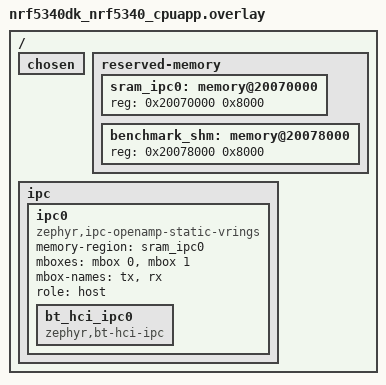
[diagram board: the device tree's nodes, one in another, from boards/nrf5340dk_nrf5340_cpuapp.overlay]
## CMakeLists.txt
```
# SPDX-License-Identifier: Apache-2.0

cmake_minimum_required(VERSION 3.20.0)

# YOUR BOARD HERE
# set(ENV{BOARD} nrf52840dk/nrf52840)
# set(ENV{BOARD} nrf5340dk/nrf5340/cpuapp)
#set(ENV{BOARD} nrf5340dk/nrf5340/cpunet)
# set(ENV{BOARD} nrf54l15dk/nrf54l15/cpuapp)

#find_package(Zephyr)
find_package(Zephyr REQUIRED HINTS $ENV{ZEPHYR_BASE})
project(ble-framework)

FILE(GLOB app_sources src/*.c)
target_sources(app PRIVATE ${app_sources})

zephyr_include_directories(
        ${CMAKE_CURRENT_SOURCE_DIR}/include
)

zephyr_include_directories_ifdef(
        CONFIG_SOC_COMPATIBLE_NRF53X
        ${CMAKE_CURRENT_SOURCE_DIR}/common_nRF5340/include
)
```

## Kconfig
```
config BENCHMARK_AUTO_DUT
	bool "Run the benchmark batch autonomously after boot (Device B / DUT on PPK II)"
	help
	  The DUT initializes, advertises, accepts the pairing of Device A and,
	  once Device A has subscribed, sends all payload sizes from
	  auto_benchmark.c on its own. The results are sent to Device A over the
	  results characteristic, so the DUT's serial terminal is never needed.
	  Build with -DEXTRA_CONF_FILE=auto_dut.conf.

config BENCHMARK_IDLE_TEST
	bool "Idle current test: step through sleep / timer / BLE phases (Device B on PPK II)"
	depends on !BENCHMARK_AUTO_DUT && SOC_COMPATIBLE_NRF52X
	help
	  Measures what the benchmark timer and Bluetooth add to the idle current.
	  See src/idle_test.c, evaluate with data_processing/idle_test.py.
	  Build with -DEXTRA_CONF_FILE=idle_test.conf.

source "Kconfig.zephyr"
```

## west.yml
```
# app_attacks/west.yml:
manifest:
  remotes:
    - name: zephyr_attacks
      url-base: https://github.com/HannahGress
  projects:
    - name: zephyr_attacks
      remote: zephyr_attacks
      revision: benchmarking-time
      import: true
```

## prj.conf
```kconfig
#
# Copyright (c) 2018 Nordic Semiconductor
#
# SPDX-License-Identifier: LicenseRef-Nordic-5-Clause
#
# Enable Security Management Protocol
CONFIG_BT_SMP=y

# Logger module
#CONFIG_LOG=y
#CONFIG_BT_LOG_SNIFFER_INFO=y
#CONFIG_LOG_PROCESS_THREAD=y
# allows to make sent packages visible ("Wireshark")
#CONFIG_BT_SMP_LOG_LEVEL_DBG=y
#CONFIG_LOG_MODE_OVERFLOW=y

#CONFIG_LOG_BUFFER_SIZE=4096

#CONFIG_BT_HCI_ERR_TO_STR=y
#CONFIG_BT_HCI_CORE_LOG_LEVEL_INF=y

CONFIG_BT=y
CONFIG_BT_CENTRAL=y
CONFIG_BT_PERIPHERAL=y
CONFIG_BT_BROADCASTER=y
CONFIG_BT_GATT_CLIENT=y
CONFIG_BT_DEVICE_NAME="BLE Framework"
# CONFIG_BT_PRIVACY gives the DK/Central a RPA instead a NRPA
CONFIG_BT_PRIVACY=y
CONFIG_BT_MAX_CONN=5
CONFIG_BT_BONDABLE=y
CONFIG_BT_SMP_APP_PAIRING_ACCEPT=y
# When a bond is about to complete, find any other bond with the same
# peer address (or IRK) and `bt_unpair` that bond before the event `pairing_complete`.
#BT_ID_UNPAIR_MATCHING_BONDS=y

# setting configurations to allow flash handling
CONFIG_BT_SETTINGS=y
CONFIG_FLASH=y
CONFIG_FLASH_PAGE_LAYOUT=y
CONFIG_FLASH_MAP=y
CONFIG_NVS=y
CONFIG_SETTINGS=y
CONFIG_SETTINGS_RUNTIME=y

# Increase the number of maximum paired devices
CONFIG_BT_MAX_PAIRED=5
CONFIG_BT_ID_MAX=20

# Increase stack size for the main thread and System Workqueue
CONFIG_SYSTEM_WORKQUEUE_STACK_SIZE=2048
CONFIG_MAIN_STACK_SIZE=2048
CONFIG_BT_RX_STACK_SIZE=2048
# CONFIG_BT_HCI_TX_STACK_SIZE_WITH_PROMPT=y
CONFIG_BT_HCI_TX_STACK_SIZE=1024

CONFIG_SHELL=y

CONFIG_BT_SMP_SC_ONLY=n
CONFIG_BT_SMP_SC_PAIR_ONLY=n

# enable data length extension
# CONFIG_BT_CTLR_DATA_LENGTH=y
CONFIG_BT_CTLR_DATA_LENGTH_MAX=251
CONFIG_BT_BUF_ACL_TX_SIZE=251
CONFIG_BT_BUF_ACL_RX_SIZE=251
CONFIG_BT_L2CAP_TX_MTU=247

CONFIG_BT_SMP_MIN_ENC_KEY_SIZE=7

# stop the scan to repeatedly showing the same devices/AD packets
CONFIG_BT_CTLR_DUP_FILTER_LEN=128

# CONFIG_SOC_NRF53_CPUNET_ENABLE=y

# to enable %f when printing (shell or printf), so printing of double and float
CONFIG_CBPRINTF_FP_SUPPORT=y

# if one board lost/deleted the LTK, pairing is started from scratch instead of throwing a pairing failure
CONFIG_BT_SMP_ALLOW_UNAUTH_OVERWRITE=y

# connection interval 100 ms (units of 1.25 ms), gives Device A more time per received packet
# The Peripheral requests these values ~5 s after connecting, and cmd_connect() uses the same
# values as Central, so the interval does not change during a measurement.
# Timeout 4 s (units of 10 ms), must be > 2 * interval
CONFIG_BT_PERIPHERAL_PREF_MIN_INT=80
CONFIG_BT_PERIPHERAL_PREF_MAX_INT=80
CONFIG_BT_PERIPHERAL_PREF_LATENCY=0
CONFIG_BT_PERIPHERAL_PREF_TIMEOUT=400
```

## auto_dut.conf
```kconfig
# Device B (DUT): run the benchmark batch autonomously after boot
# build with -DEXTRA_CONF_FILE=auto_dut.conf
CONFIG_BENCHMARK_AUTO_DUT=y

# ###########################################################################
# /!\ THE SERIAL SHELL OF THIS BUILD IS DISABLED /!\
#
# The UART keeps drawing ~1 mA even without USB, which distorts the current
# measurement. Shell output goes to a dummy backend (nowhere) instead, so the
# serial terminal of Device B shows NOTHING and accepts NO commands.
#
# To talk to Device B over its serial terminal again, delete or comment out
# the three lines below and rebuild + reflash (or use the normal build).
# ###########################################################################
# SHELL_BACKEND_SERIAL selects SERIAL, so without this line SERIAL silently stays y
CONFIG_SHELL_BACKEND_SERIAL=n
CONFIG_SERIAL=n
CONFIG_SHELL_BACKEND_DUMMY=y
```

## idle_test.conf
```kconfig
# Device B: idle current test, see src/idle_test.c and data_processing/idle_test.py
# build with -DEXTRA_CONF_FILE=idle_test.conf
CONFIG_BENCHMARK_IDLE_TEST=y

# serial shell disabled like in auto_dut.conf: the UART alone draws ~1 mA
# SHELL_BACKEND_SERIAL selects SERIAL, so it has to be switched off too, otherwise SERIAL stays y
CONFIG_SHELL_BACKEND_SERIAL=n
CONFIG_SERIAL=n
CONFIG_SHELL_BACKEND_DUMMY=y
```

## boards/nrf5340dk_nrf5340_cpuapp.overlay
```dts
/delete-node/ &sram0_shared;

/ {
	chosen {
		/delete-property/ zephyr,ipc_shm;
	};

	reserved-memory {
		#address-cells = <1>;
		#size-cells = <1>;
		ranges;

		sram_ipc0: memory@20070000 {
			reg = <0x20070000 0x8000>;
		};

		benchmark_shm: memory@20078000 {
			reg = <0x20078000 0x8000>;
		};
	};

	ipc {
		/delete-node/ ipc0;

		ipc0: ipc0 {
			compatible = "zephyr,ipc-openamp-static-vrings";
			memory-region = <&sram_ipc0>;

			mboxes = <&mbox 0>, <&mbox 1>;
			mbox-names = "tx", "rx";

			role = "host";
			status = "okay";

			bt_hci_ipc0: bt_hci_ipc0 {
				compatible = "zephyr,bt-hci-ipc";
				status = "okay";
			};
		};
	};
};
```

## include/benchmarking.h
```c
#pragma once

extern int cmd_benchmark();
extern int cmd_reset_sum_delta();
extern int cmd_get_delta_encryption_time();
extern int cmd_get_time_results();
extern int cmd_get_time_results_extended();
extern void reset_values();
extern void benchmark_on(void);
extern void benchmark_off(void);
```

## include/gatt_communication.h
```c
#pragma once

#include <stdbool.h>
#include <stdint.h>

extern volatile bool notification_sent;
extern bool notify_enabled;
extern bool results_notify_enabled;
// suppresses the per-packet shell output of notify_complete_cb during a measurement
extern volatile bool benchmark_quiet;
extern const struct bt_gatt_service_static notification_srv;
extern int send_notification(struct bt_conn *conn,
                             const struct bt_gatt_attr *attr, int payload_size);
extern int send_results(struct bt_conn *conn, const uint8_t *data, uint16_t len);
extern int start_discovery(struct bt_conn *conn);
extern int subscribe_all(struct bt_conn *conn);
extern struct bt_gatt_subscribe_params subscribe_params;
extern struct bt_gatt_discover_params discover_params;

/*
 * Records on the results characteristic (DUT -> Device A), little endian.
 * The first byte of every notification is the record type.
 *   BEGIN:      type, payload_size, packets_sent (u16), count (u16), fields_per_record, timer_hz (u32)
 *   DATA:       type, payload_size, first_index (u16), n_records, n_records * fields_per_record * u32 (raw timer ticks)
 *   END:        type, payload_size
 *   BATCH_DONE: type
 */
#define RESULTS_BEGIN        1
#define RESULTS_DATA         2
#define RESULTS_END          3
#define RESULTS_BATCH_DONE   4

#define RESULTS_BEGIN_LEN       11
#define RESULTS_DATA_HEADER_LEN 5

/*
 * Record on the control characteristic (Device A -> DUT), little endian.
 *   RUN: type, payload_size, packets (u16)
 */
#define CONTROL_RUN     1
#define CONTROL_RUN_LEN 4

// Device A: write a RUN record to the DUT
extern int request_run(struct bt_conn *conn, uint8_t payload_size, uint16_t packets);

// DUT: the latest RUN request, given via run_request_sem
extern struct k_sem run_request_sem;
extern volatile uint8_t run_request_payload_size;
extern volatile uint16_t run_request_packets;
```

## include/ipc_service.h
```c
int benchmark_ipc_init(void);
int send_signal_nRF5340_dppi_config();
int send_signal_nRF5340_dppi_disable();
```

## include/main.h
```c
#pragma once

#include <stdbool.h>

struct bt_conn;  // forward declaration (sufficient for pointer)
extern struct bt_conn *default_conn;
extern const struct shell *shell;
int w_advertising_start(void);
int ble_init(void);
void idle_test_run(void);  // src/idle_test.c, CONFIG_BENCHMARK_IDLE_TEST
int send_packets(int n, int payload_size, bool quiet);
```

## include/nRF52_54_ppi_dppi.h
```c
#pragma once

#include <stdbool.h>
#include <stdint.h>

#if defined(CONFIG_SOC_COMPATIBLE_NRF52X)
#include <zephyr/bluetooth/conn.h>

/*
 * For benchmarking the nRF52840
 * Timer offsets /variables for capturing start and end of KSGEN and de-/encryption
 */

/* KSGEN */
#define HAL_EVENT_TIMER_KSGEN_START_ENC_CC_OFFSET 0
#define HAL_EVENT_TIMER_KSGEN_START_DECR_CC_OFFSET 1
/* Timer for the end of KSGEN*/
#define HAL_EVENT_TIMER_KSGEN_END_CC_OFFSET 2

/*
 * Different timer for encryption and decryption start, but the end event is the same, so we only need one timer for the end event.
 */
#define HAL_EVENT_TIMER_CCM_START_ENC_CC_OFFSET 3
#define HAL_EVENT_TIMER_CCM_START_DECR_CC_OFFSET 4
#define HAL_EVENT_TIMER_CCM_END_ENDCRYPT_CC_OFFSET 5

/*
 * channel to capture start & end of KSGEN, encryption or decryption
 */

/*
 * Channel for the end of KSGEN (CC[2]); its FORK also captures the encryption start (CC[3]),
 * because the encryption starts on that same ENDKSGEN event (ENDKSGEN_CRYPT short)
 */
#define HAL_CRYPT_END_TIME_KSGEN_PPI 0

/* Different channel for decryption start, but the end event is the same, so we only need one channel for the end event */
#define HAL_CRYPT_START_TIME_DECRYPT_PPI 2
#define HAL_CRYPT_END_TIME_ENDCRYPT_PPI 3

/*
 * KSGEN START IN HARDWARE (TX only)
 *
 * The CCM has no "KSGEN started" event. So while benchmarking, radio.c triggers
 * EGU0 instead of CCM TASKS_KSGEN, and this PPI channel starts KSGEN (TEP) and
 * captures t_start_KSGEN in TIMER3 CC[0] (FORK) on the same clock edge, no CPU
 * cycles in between. It is only enabled in benchmark_on(); otherwise radio.c
 * starts KSGEN directly, so encryption never depends on this channel.
 * EGU0/SWI0 is unused here (the controller only uses the SWI4/SWI5 IRQs) and
 * its interrupt stays disabled.
 *
 * /!\ Must be a channel no driver allocates at runtime: Zephyr's nrfx allocator
 * hands out the HIGHEST free channel first (e.g. the UART takes 19 for
 * ENDTX->STOPTX on boards with a serial console). Channel 1 is handed out last.
 */
#define KSGEN_START_EGU_EVENT        0   /* NRF_EGU0 TASKS_TRIGGER/EVENTS_TRIGGERED[0] */
#define KSGEN_START_ENC_PPI          1

/*
 * KSGEN MARKER (active low) on P0.<KSGEN_MARKER_PIN> -> wire to PPK II D0
 *
 * Goes LOW for the keystream generation of a benchmarked notification only:
 *   EGU0 (= KSGEN start)  -> pin LOW
 *   CCM EVENTS_ENDKSGEN   -> pin HIGH
 * The DATA-PACKET MARKER on P0.04 (D1) below goes LOW on that same ENDKSGEN
 * edge, so per packet the PPK II sees a D0 pulse directly followed by a D1 pulse
 * (KSGEN, then encryption). Gated per packet exactly like P0.04 (enabled by the
 * filter in lll_conn.c, disabled in lll_conn_isr_tx).
 */
#define KSGEN_MARKER_PORT            0   /* GPIO port: P0 -> 0, P1 -> 1         */
#define KSGEN_MARKER_PIN             3   /* P0.03: free on the DK (no LED/button,
                                          * draws no current of its own)        */
#define KSGEN_MARKER_GPIOTE_CH       0   /* free GPIOTE channel (0..7)          */
#define KSGEN_MARKER_START_PPI       4   /* free PPI channel: pin -> LOW       */
#define KSGEN_MARKER_END_PPI         5   /* free PPI channel: pin -> HIGH      */

/*
 * DATA-PACKET MARKER (active low) on P0.<PACKET_MARKER_PIN>  -> wire to PPK II D1
 *
 * It goes LOW ONLY for the encryption of a real send_data notification
 * (KSGEN excluded, that one is on P0.03 / D0 above).
 *
 * Wired to the CCM events (ENDKSGEN -> LOW, ENDCRYPT -> HIGH) over PPI +
 * GPIOTE, so the pin edges are hardware-crisp with
 * no software jitter. The difference: these two PPI channels are kept DISABLED
 * by default and only enabled, per packet, by the `benchmarked_tx_packet`
 * filter in the controller (lll_conn.c) for a real send_data TX encryption,
 * then disabled again in lll_conn_isr_tx. That gates the hardware marker with
 * the software decision without ever lagging the pin edges.
 */
#define PACKET_MARKER_PORT           0   /* GPIO port: P0 -> 0, P1 -> 1         */
#define PACKET_MARKER_PIN            4   /* P0.04 (AIN2): free on the DK        */
#define PACKET_MARKER_GPIOTE_CH      1   /* free GPIOTE channel (0..7)          */
/* NOTE: PPI 6 and 7 are NOT free, the BLE controller owns them
 * (HAL_EVENT_TIMER_START_PPI / HAL_RADIO_READY_TIME_CAPTURE_PPI) and touching
 * them causes supervision timeouts (0x08). 17/18/19 are only used by the
 * controller with Coded PHY or direction finding enabled, recheck
 * radio_nrf5_ppi_resources.h if you turn those on. 19 is taken by the UART
 * driver at runtime (see KSGEN_START_ENC_PPI above), so 17/18 are the next
 * ones it would hand out if another driver allocates a PPI channel. */
#define PACKET_MARKER_ENC_START_PPI  17  /* free PPI channel: pin -> LOW       */
#define PACKET_MARKER_ENC_END_PPI    18  /* free PPI channel: pin -> HIGH      */

void hal_radio_ccm_nRF52840_ppi_config();

/* We only have KSGEN in the AES-CCM peripheral of the nRF52840 (and nRF5340, but its values are defined elsewhere) */
/* The nRF54L15 spec does not mention KSGEN as part of the AES-CCm peripheral task */

/*
 * Benchmark timer (TIMER3): f_timer = BENCHMARK_TIMER_BASE_FREQ_HZ / 2^BENCHMARK_TIMER_PRESCALER
 * init_timer() in main.c programs BENCHMARK_TIMER_PRESCALER, and TIMER_TICK_NS is
 * derived from the same two values, so the conversion to ns can't get out of sync.
 * 16 MHz, prescaler 0 -> 62.5 ns per tick (32 bit wraps after ~268 s).
 */
#define BENCHMARK_TIMER_BASE_FREQ_HZ 16000000UL
#define BENCHMARK_TIMER_PRESCALER    0
static const double TIMER_TICK_NS =
    1e9 / (double)(BENCHMARK_TIMER_BASE_FREQ_HZ >> BENCHMARK_TIMER_PRESCALER);

// given by radio ISR (lll_conn_isr_tx) when a new encryption measurement is stored
extern struct k_sem encryption_measurement_sem;


/* We must declare the payload as an external variable, because we later filter for packages with this payload + 7 Bytes header data (+ other data) */
extern volatile int payload_size_i;
extern volatile struct benchmark_measurement encryption_measurement;
extern volatile struct benchmark_measurement decryption_measurement;

struct benchmark_measurement {
 uint32_t t_start_KSGEN;
 uint32_t t_end_KSGEN;
 uint32_t delta_KSGEN;

 uint32_t t_start_ENDCRYPT;
 uint32_t t_end_ENDCRYPT;
 uint32_t delta_ENDCRYPT;
};

/* we allow a maximum of 100 packets transmitted per send_data() method */
#define SUM_ARRAY_MAX_SIZE 100
extern volatile struct benchmark_measurement encryption_measurements[SUM_ARRAY_MAX_SIZE];
extern volatile struct benchmark_measurement decryption_measurements[SUM_ARRAY_MAX_SIZE];
extern volatile uint32_t encryption_measurement_count;
extern volatile uint32_t decryption_measurement_count;
#endif

#if defined(CONFIG_SOC_COMPATIBLE_NRF5340_CPUAPP)
// variables etc. are in shared_variables.h
/* Since our timer runs at 16 MHz, each tick is 62.5 ns. Therefore, we must multiply our results with this number */
static const double TIMER_TICK_NS = 62.5;
#endif

#if defined(CONFIG_SOC_COMPATIBLE_NRF54LX)

/*
 * ENCRYPTION
 * we don't need a separate encryption DPPI channel
 * For encryption, we capture the appropriate function call;
 * Everything related to encryption is 0; Decryption is 1 and ENDCRYPT 2
 * For decryption. we can listen to the existing one of Zephyr, but need some additional channels and PPI Bridges
 * The same applies for ENDCRYPT
 */

/*
 * DECRYPTION
 * We must pass an Event from one PPI Domain to another (RADIO to PERI(PHERAL)), therefore, we need a PPI Bridge (PPIB)
 * Since we work in different domains and bridges, the channel numbers can be the same, because the channels are different
 * in/for each domain/bridge
 */
//#define DECRYPT_START_RADIO_DPPI_CHANNEL  1
//#define DECRYPT_START_PPIB_CHANNEL  1
//#define DECRYPT_START_MCU_DPPI_CHANNEL  1

/*
 * ENDCRYPT
 * Measurement in the MCU domain
 */
#define ENDCRYPT_DPPI_CHANNEL 3

extern void hal_radio_ccm_nRF54L15_ppi_config(void);
extern void hal_radio_ccm_nRF54L15_ppi_disable(void);

/*
 * Benchmark timer (TIMER00): f_timer = BENCHMARK_TIMER_BASE_FREQ_HZ / 2^BENCHMARK_TIMER_PRESCALER
 * init_timer() in main.c programs BENCHMARK_TIMER_PRESCALER, and TIMER_TICK_NS is
 * derived from the same two values, so the conversion to ns can't get out of sync.
 * TIMER00 is clocked at 128 MHz, prescaler 0 -> 7.8125 ns per tick (32 bit wraps after ~33 s).
 */
#define BENCHMARK_TIMER_BASE_FREQ_HZ 128000000UL
#define BENCHMARK_TIMER_PRESCALER    0
static const double TIMER_TICK_NS =
    1e9 / (double)(BENCHMARK_TIMER_BASE_FREQ_HZ >> BENCHMARK_TIMER_PRESCALER);

// Given by the radio ISR (lll_conn_isr_tx) when a new encryption measurement is stored
extern struct k_sem encryption_measurement_sem;

/* We must declare the payload as an external variable, because we later filter for packages with this payload + 7 Bytes header data (+ other data) */
extern volatile int payload_size_i;

/* /!\ we only save ticks in the structs and multiply by TIMER_TICK_NS when printing the values (less time critical and more efficient) */
extern volatile struct benchmark_measurement encryption_measurement;
extern volatile struct benchmark_measurement decryption_measurement;

struct benchmark_measurement {
 uint32_t t_start_ENDCRYPT;
 uint32_t t_end_ENDCRYPT;
 uint32_t delta_ENDCRYPT;
};

/* we allow a maximum of 100 packets transmitted per send_data() method */
#define SUM_ARRAY_MAX_SIZE 100
/* /!\ we only save ticks in the arrazy and multiply by TIMER_TICK_NS when printing the values (less time critical and more efficient) */
extern volatile struct benchmark_measurement encryption_measurements[SUM_ARRAY_MAX_SIZE];
extern volatile struct benchmark_measurement decryption_measurements[SUM_ARRAY_MAX_SIZE];
extern volatile uint32_t encryption_measurement_count;
extern volatile uint32_t decryption_measurement_count;
#endif
```

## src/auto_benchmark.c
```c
/*
 * Device B (DUT) runs the benchmark on its own, so it can be powered by the PPK II
 * without USB/serial terminal (build with -DEXTRA_CONF_FILE=auto_dut.conf).
 * Same steps as the "under the hood" table in the README:
 *   init -> advertise start -> (Device A pairs, discovers, subscribes)
 *   per "bleframework run <payload_size> [n]" on Device A (control characteristic):
 *   benchmark on -> idle gap -> n packets -> idle gap -> benchmark off -> results to Device A
 */

#include <zephyr/kernel.h>
#include <zephyr/bluetooth/bluetooth.h>
#include <zephyr/bluetooth/conn.h>
#include <zephyr/bluetooth/gatt.h>
#include <zephyr/sys/byteorder.h>
#include <zephyr/sys/util.h>
#include <zephyr/shell/shell.h>
#include <main.h>
#include <gatt_communication.h>
#include <benchmarking.h>
#include <auto_benchmark.h>
#if defined(CONFIG_SOC_COMPATIBLE_NRF54LX) || defined(CONFIG_SOC_COMPATIBLE_NRF52X)
#include <nRF52_54_ppi_dppi.h>
#elif defined(CONFIG_SOC_COMPATIBLE_NRF5340_CPUAPP)
#include <shared_variables.h>
#include <nRF52_54_ppi_dppi.h>
#endif

#if defined(CONFIG_BENCHMARK_AUTO_DUT)

#define BOOT_DELAY_MS 2000
/* quiet time before and after each block, gives every PPK II recording a clean baseline */
#define IDLE_GAP_MS 500

/* raw timer ticks per record; the nRF54L CCM has no separate KSGEN step */
#if defined(CONFIG_SOC_COMPATIBLE_NRF54LX)
#define FIELDS_PER_RECORD 3
#else
#define FIELDS_PER_RECORD 6
#endif

#if defined(CONFIG_SOC_COMPATIBLE_NRF5340_CPUAPP)
#define BENCHMARK_TIMER_HZ 16000000UL
#else
#define BENCHMARK_TIMER_HZ (BENCHMARK_TIMER_BASE_FREQ_HZ >> BENCHMARK_TIMER_PRESCALER)
#endif

static uint32_t enc_count(void)
{
	#if defined(CONFIG_SOC_COMPATIBLE_NRF5340_CPUAPP)
	uint32_t count = NRF5340_SHARED_VARIABLES->benchmark_results.encryption_measurement_count;
	#else
	uint32_t count = encryption_measurement_count;
	#endif

	return MIN(count, SUM_ARRAY_MAX_SIZE);
}

static void enc_get(uint32_t i, uint32_t fields[FIELDS_PER_RECORD])
{
	#if defined(CONFIG_SOC_COMPATIBLE_NRF5340_CPUAPP)
	struct benchmark_measurement m = NRF5340_SHARED_VARIABLES->benchmark_results.encryption_measurements[i];
	#else
	struct benchmark_measurement m = encryption_measurements[i];
	#endif

	#if defined(CONFIG_SOC_COMPATIBLE_NRF54LX)
	fields[0] = m.t_start_ENDCRYPT;
	fields[1] = m.t_end_ENDCRYPT;
	fields[2] = m.delta_ENDCRYPT;
	#else
	fields[0] = m.t_start_KSGEN;
	fields[1] = m.t_end_KSGEN;
	fields[2] = m.delta_KSGEN;
	fields[3] = m.t_start_ENDCRYPT;
	fields[4] = m.t_end_ENDCRYPT;
	fields[5] = m.delta_ENDCRYPT;
	#endif
}

// 0 never matches a notification (len == payload_size + 7), so the results are not measured and P0.04 stays quiet
static void clear_payload_filter(void)
{
	#if defined(CONFIG_SOC_COMPATIBLE_NRF5340_CPUAPP)
	NRF5340_SHARED_VARIABLES->benchmark_control.payload_size = 0;
	#else
	payload_size_i = 0;
	#endif
}

static bool link_ready(void)
{
	return default_conn &&
	       bt_conn_get_security(default_conn) >= BT_SECURITY_L2 &&
	       notify_enabled && results_notify_enabled;
}

static int dump_results(uint8_t payload_size, uint16_t packets_sent)
{
	uint8_t buf[RESULTS_DATA_HEADER_LEN + 244];
	uint32_t fields[FIELDS_PER_RECORD];
	uint16_t count = enc_count();
	int err;

	buf[0] = RESULTS_BEGIN;
	buf[1] = payload_size;
	sys_put_le16(packets_sent, &buf[2]);
	sys_put_le16(count, &buf[4]);
	buf[6] = FIELDS_PER_RECORD;
	sys_put_le32(BENCHMARK_TIMER_HZ, &buf[7]);

	err = send_results(default_conn, buf, RESULTS_BEGIN_LEN);
	if (err) {
		return err;
	}

	// as many records as fit into one notification (ATT MTU - 3, max. 244)
	uint16_t max_len = MIN(bt_gatt_get_mtu(default_conn) - 3, 244);
	uint8_t records_per_packet = (max_len - RESULTS_DATA_HEADER_LEN) / (FIELDS_PER_RECORD * 4);

	for (uint16_t first = 0; first < count; first += records_per_packet) {
		uint8_t n_records = MIN(records_per_packet, count - first);
		uint8_t *value = &buf[RESULTS_DATA_HEADER_LEN];

		buf[0] = RESULTS_DATA;
		buf[1] = payload_size;
		sys_put_le16(first, &buf[2]);
		buf[4] = n_records;

		for (int r = 0; r < n_records; r++) {
			enc_get(first + r, fields);
			for (int f = 0; f < FIELDS_PER_RECORD; f++) {
				sys_put_le32(fields[f], value);
				value += 4;
			}
		}

		err = send_results(default_conn, buf, value - buf);
		if (err) {
			return err;
		}
	}

	buf[0] = RESULTS_END;
	buf[1] = payload_size;

	return send_results(default_conn, buf, 2);
}

void auto_benchmark_run(void)
{
	int err;

	k_sleep(K_MSEC(BOOT_DELAY_MS));

	err = ble_init();
	if (err) {
		shell_error(shell, "[AUTO] Bluetooth init failed (err %d)", err);
		return;
	}

	// pair from scratch every run, so the pairing configuration of Device A (knob/scda) applies
	(void)bt_unpair(BT_ID_DEFAULT, NULL);

	w_advertising_start();
	shell_print(shell, "[AUTO] Waiting for Device A to pair and subscribe...");

	while (!link_ready()) {
		k_sleep(K_MSEC(100));
	}

	shell_print(shell, "[AUTO] Device A ready, waiting for run requests");

	while (true) {
		k_sem_take(&run_request_sem, K_FOREVER);

		uint8_t payload_size = run_request_payload_size;
		uint16_t packets = run_request_packets;

		// also resets the arrays and counters
		benchmark_on();
		k_sleep(K_MSEC(IDLE_GAP_MS));

		err = send_packets(packets, payload_size, true);
		if (err) {
			shell_error(shell, "[AUTO] Sending payload %u failed (err %d)", payload_size, err);
		}

		k_sleep(K_MSEC(IDLE_GAP_MS));
		benchmark_off();
		clear_payload_filter();

		// sent even after a send error, A waits for RES_END and sees count < packets
		err = dump_results(payload_size, packets);
		if (err) {
			shell_error(shell, "[AUTO] Sending the results of payload %u failed (err %d)", payload_size, err);
		}
	}
}

#endif /* CONFIG_BENCHMARK_AUTO_DUT */
```

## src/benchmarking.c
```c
#include <main.h>
#include <benchmarking.h>
#include <stdlib.h>
#include <zephyr/shell/shell.h>
#include <zephyr/sys/util.h>

#if defined(CONFIG_SOC_COMPATIBLE_NRF52X)
#include <nRF52_54_ppi_dppi.h>
#include <controller/ll_sw/nordic/hal/nrf5/radio/radio_nrf5_ppi.h>
#include "zephyr/bluetooth/conn.h"
#include "zephyr/bluetooth/hci.h"
#include <main.h>
#endif

#if defined(CONFIG_SOC_COMPATIBLE_NRF54LX)
#include <nRF52_54_ppi_dppi.h>
#endif

#if defined(CONFIG_SOC_COMPATIBLE_NRF5340_CPUAPP)
#include <shared_variables.h>
#include <ipc_service.h>
#include <nRF52_54_ppi_dppi.h>
#endif

void benchmark_on(void) {

    #if defined(CONFIG_SOC_COMPATIBLE_NRF52X)

    hal_radio_ccm_nRF52840_ppi_config();

    // enable the PPI channels (incl. the hardware KSGEN start; the P0.03/P0.04 markers are enabled per packet in lll_conn.c)
    nrf_ppi_channels_enable(NRF_PPI,
        BIT(KSGEN_START_ENC_PPI) | BIT(HAL_CRYPT_END_TIME_KSGEN_PPI) |
        BIT(HAL_CRYPT_START_TIME_DECRYPT_PPI) | BIT(HAL_CRYPT_END_TIME_ENDCRYPT_PPI));

    /* reset all values to not disturb the measurements */
    reset_values();

    #elif defined(CONFIG_SOC_COMPATIBLE_NRF5340_CPUAPP)

    send_signal_nRF5340_dppi_config();

    /* reset all values to not disturb the measurements */
    reset_values();

    #elif defined(CONFIG_SOC_COMPATIBLE_NRF54LX)

    hal_radio_ccm_nRF54L15_ppi_config();

    /* reset all values to not disturb the measurements */
    reset_values();

    #endif

    shell_print(shell, "Benchmarking successfully enabled.");
}

void benchmark_off(void) {

    #if defined(CONFIG_SOC_COMPATIBLE_NRF52X)
    // without KSGEN_START_ENC_PPI, radio.c starts KSGEN in software again
    nrf_ppi_channels_disable(NRF_PPI,
        BIT(KSGEN_START_ENC_PPI) | BIT(HAL_CRYPT_END_TIME_KSGEN_PPI) |
        BIT(HAL_CRYPT_START_TIME_DECRYPT_PPI) | BIT(HAL_CRYPT_END_TIME_ENDCRYPT_PPI));
    #elif defined(CONFIG_SOC_COMPATIBLE_NRF5340_CPUAPP )
    send_signal_nRF5340_dppi_disable();
    #elif defined(CONFIG_SOC_COMPATIBLE_NRF54LX)
    hal_radio_ccm_nRF54L15_ppi_disable();
    #endif

    shell_print(shell, "Benchmarking successfully disabled.");
}

int cmd_benchmark(const struct shell *sh, size_t argc, char *argv[])
{
    // we can turn on and off the benchmarking
    const char *on_off = NULL;

    // We need all arguments for the benchmarking
    if (argc < 2) {
        shell_error(sh, "Wrong number of arguments.");
        shell_help(sh);
        return SHELL_CMD_HELP_PRINTED;
    }

    on_off = argv[1];
    if (*on_off == '\0') {
        shell_error(sh, "Argument must not be empty.");
        return -EINVAL;
    }
    if (!strcmp(on_off, "on")) {
        benchmark_on();
    } else if (!strcmp(on_off, "off")) {
        benchmark_off();
    } else {
        shell_help(sh);
        return SHELL_CMD_HELP_PRINTED;
    }
    return 0;
}


// average over array of timer data
// reset_values to clear for next benchmarking
int cmd_get_time_results(const struct shell *sh, size_t argc, char *argv[]) {

    #if defined(CONFIG_SOC_COMPATIBLE_NRF52X)

    /* get the length of value array encryption_measurements and decryption_measurements */
    int length_values_ENCRYPT = sizeof(encryption_measurements) / sizeof(encryption_measurements[0]);
    int length_values_DECRYPT = sizeof(decryption_measurements) / sizeof(decryption_measurements[0]);

    double sum_KSGEN_ENCRYPT = 0;
    double sum_ENCRYPT = 0;
    double sum_KSGEN_DECRYPT = 0;
    double sum_DECRYPT = 0;

    int i = 0;
    int j = 0;

    while(i < MIN(encryption_measurement_count, length_values_ENCRYPT)) {
        sum_KSGEN_ENCRYPT += encryption_measurements[i].delta_KSGEN * TIMER_TICK_NS;
        sum_ENCRYPT += encryption_measurements[i].delta_ENDCRYPT * TIMER_TICK_NS;
        i++;
    }

    while(j < MIN(decryption_measurement_count, length_values_DECRYPT)) {
        sum_KSGEN_DECRYPT += decryption_measurements[j].delta_KSGEN * TIMER_TICK_NS;
        sum_DECRYPT += decryption_measurements[j].delta_ENDCRYPT * TIMER_TICK_NS;
        j++;
    }

    double avg_KSGEN_ENCRYPT = (i > 0) ? sum_KSGEN_ENCRYPT / i : 0.0;
    double avg_ENCRYPT = (i > 0) ? sum_ENCRYPT / i : 0.0;
    double avg_KSGEN_DECRYPT = (j > 0) ? sum_KSGEN_DECRYPT / j : 0.0;
    double avg_DECRYPT = (j > 0) ? sum_DECRYPT / j : 0.0;

    if(avg_ENCRYPT != 0) {
        shell_print(sh, "avg_KSGEN_ENCRYPT: %f ns", avg_KSGEN_ENCRYPT);
        shell_print(sh, "avg_ENCRYPT: %f ns", avg_ENCRYPT);
    }
    else if(avg_DECRYPT != 0) {
        shell_print(sh, "avg_KSGEN_DECRYPT: %f ns", avg_KSGEN_DECRYPT);
        shell_print(sh, "avg_DECRYPT: %f ns", avg_DECRYPT);
    }
    else {
        shell_print(sh, "No results for key stream generation, encryption and decryption (yet). You must first run send_data <n> <payload> to create some.");
    }

    #elif defined(CONFIG_SOC_COMPATIBLE_NRF5340_CPUAPP)

    /* get the length of value array encryption_measurements and decryption_measurements */
    int length_values_ENCRYPT = sizeof(NRF5340_SHARED_VARIABLES->benchmark_results.encryption_measurements) / sizeof(NRF5340_SHARED_VARIABLES->benchmark_results.encryption_measurements[0]);
    int length_values_DECRYPT = sizeof(NRF5340_SHARED_VARIABLES->benchmark_results.decryption_measurements) / sizeof(NRF5340_SHARED_VARIABLES->benchmark_results.decryption_measurements[0]);

    double sum_KSGEN_ENCRYPT = 0;
    double sum_ENCRYPT = 0;
    double sum_KSGEN_DECRYPT = 0;
    double sum_DECRYPT = 0;

    int i = 0;
    int j = 0;

    while(i < MIN(NRF5340_SHARED_VARIABLES->benchmark_results.encryption_measurement_count, length_values_ENCRYPT)) {
        sum_KSGEN_ENCRYPT += NRF5340_SHARED_VARIABLES->benchmark_results.encryption_measurements[i].delta_KSGEN * TIMER_TICK_NS;
        sum_ENCRYPT += NRF5340_SHARED_VARIABLES->benchmark_results.encryption_measurements[i].delta_ENDCRYPT * TIMER_TICK_NS;
        i++;
    }

    while(j < MIN(NRF5340_SHARED_VARIABLES->benchmark_results.decryption_measurement_count, length_values_DECRYPT)) {
        sum_KSGEN_DECRYPT += NRF5340_SHARED_VARIABLES->benchmark_results.decryption_measurements[j].delta_KSGEN * TIMER_TICK_NS;
        sum_DECRYPT += NRF5340_SHARED_VARIABLES->benchmark_results.decryption_measurements[j].delta_ENDCRYPT * TIMER_TICK_NS;
        j++;
    }

    double avg_KSGEN_ENCRYPT = (i > 0) ? sum_KSGEN_ENCRYPT / i : 0.0;
    double avg_ENCRYPT = (i > 0) ? sum_ENCRYPT / i : 0.0;
    double avg_KSGEN_DECRYPT = (j > 0) ? sum_KSGEN_DECRYPT / j : 0.0;
    double avg_DECRYPT = (j > 0) ? sum_DECRYPT / j : 0.0;

    if(avg_ENCRYPT != 0) {
        shell_print(sh, "avg_KSGEN_ENCRYPT: %f ns", avg_KSGEN_ENCRYPT);
        shell_print(sh, "avg_ENCRYPT: %f ns", avg_ENCRYPT);
    }
    else if(avg_DECRYPT != 0) {
        shell_print(sh, "avg_KSGEN_DECRYPT: %f ns", avg_KSGEN_DECRYPT);
        shell_print(sh, "avg_DECRYPT: %f ns", avg_DECRYPT);
    }
    else {
        shell_print(sh, "No results for key stream generation, encryption and decryption (yet). You must first run send_data <n> <payload> to create some.");
    }

    #elif defined(CONFIG_SOC_COMPATIBLE_NRF54LX)

    /* get the length of value array encryption_measurements and decryption_measurements */
    int length_values_ENCRYPT = sizeof(encryption_measurements) / sizeof(encryption_measurements[0]);
    int length_values_DECRYPT = sizeof(decryption_measurements) / sizeof(decryption_measurements[0]);

    double sum_ENCRYPT = 0;
    double sum_DECRYPT = 0;

    int i = 0;
    int j = 0;

    while(i < MIN(encryption_measurement_count, length_values_ENCRYPT)) {
        sum_ENCRYPT += encryption_measurements[i].delta_ENDCRYPT * TIMER_TICK_NS;
        i++;
    }

    while(j < MIN(decryption_measurement_count, length_values_DECRYPT)) {
        sum_DECRYPT += decryption_measurements[j].delta_ENDCRYPT * TIMER_TICK_NS;
        j++;
    }

    double avg_ENCRYPT = (i > 0) ? sum_ENCRYPT / i : 0.0;
    double avg_DECRYPT = (j > 0) ? sum_DECRYPT / j : 0.0;

    if(avg_ENCRYPT != 0) {
        shell_print(sh, "avg_ENCRYPT: %f ns", avg_ENCRYPT);
    }
    else if(avg_DECRYPT != 0) {
        shell_print(sh, "avg_DECRYPT: %f ns", avg_DECRYPT);
    }
    else {
        shell_print(sh, "No results for encryption and decryption (yet). You must first run send_data <n> <payload> to create some.");
    }

    #endif

    return 0;
}

int cmd_get_time_results_extended(const struct shell *sh, size_t argc, char *argv[]) {

#if defined(CONFIG_SOC_COMPATIBLE_NRF52X)

    /* get the length of value array encryption_measurements and decryption_measurements */
    int length_values_ENCRYPT = sizeof(encryption_measurements) / sizeof(encryption_measurements[0]);
    int length_values_DECRYPT = sizeof(decryption_measurements) / sizeof(decryption_measurements[0]);

    int i = 0;
    int j = 0;

    while(i < MIN(encryption_measurement_count, length_values_ENCRYPT)) {
        shell_print(sh, "Iteration %u: \n", i);
        shell_print(sh, "start_KSGEN %f: ns\n", encryption_measurements[i].t_start_KSGEN * TIMER_TICK_NS);
        shell_print(sh, "end_KSGEN %f: ns\n", encryption_measurements[i].t_end_KSGEN * TIMER_TICK_NS);
        shell_print(sh, "delta_KSGEN %f: ns\n", encryption_measurements[i].delta_KSGEN * TIMER_TICK_NS);
        shell_print(sh, "start_ENCRYPT %f: ns\n", encryption_measurements[i].t_start_ENDCRYPT * TIMER_TICK_NS);
        shell_print(sh, "end_ENCRYPT %f: ns\n", encryption_measurements[i].t_end_ENDCRYPT * TIMER_TICK_NS);
        shell_print(sh, "delta_ENCRYPT %f: ns\n", encryption_measurements[i].delta_ENDCRYPT * TIMER_TICK_NS);
        i ++;
    }

    while(j < MIN(decryption_measurement_count, length_values_DECRYPT)) {
        shell_print(sh, "Iteration %u: \n", j);
        shell_print(sh, "start_KSGEN %f: ns\n", decryption_measurements[j].t_start_KSGEN * TIMER_TICK_NS);
        shell_print(sh, "end_KSGEN %f: ns\n", decryption_measurements[j].t_end_KSGEN * TIMER_TICK_NS);
        shell_print(sh, "delta_KSGEN %f: ns\n", decryption_measurements[j].delta_KSGEN * TIMER_TICK_NS);
        shell_print(sh, "start_DECRYPT %f: ns\n", decryption_measurements[j].t_start_ENDCRYPT * TIMER_TICK_NS);
        shell_print(sh, "end_DECRYPT %f: ns\n", decryption_measurements[j].t_end_ENDCRYPT * TIMER_TICK_NS);
        shell_print(sh, "delta_DECRYPT %f: ns\n", decryption_measurements[j].delta_ENDCRYPT * TIMER_TICK_NS);
        j++;
    }

    #elif defined(CONFIG_SOC_COMPATIBLE_NRF5340_CPUAPP)

    /* get the length of value array encryption_measurements and decryption_measurements */
    int length_values_ENCRYPT = sizeof(NRF5340_SHARED_VARIABLES->benchmark_results.encryption_measurements) / sizeof(NRF5340_SHARED_VARIABLES->benchmark_results.encryption_measurements[0]);
    int length_values_DECRYPT = sizeof(NRF5340_SHARED_VARIABLES->benchmark_results.decryption_measurements) / sizeof(NRF5340_SHARED_VARIABLES->benchmark_results.decryption_measurements[0]);

    int i = 0;
    int j = 0;

    while(i < MIN(NRF5340_SHARED_VARIABLES->benchmark_results.encryption_measurement_count, length_values_ENCRYPT)) {
        shell_print(sh, "Iteration %u: \n", i);
        shell_print(sh, "start_KSGEN %f: ns\n", NRF5340_SHARED_VARIABLES->benchmark_results.encryption_measurements[i].t_start_KSGEN * TIMER_TICK_NS);
        shell_print(sh, "end_KSGEN %f: ns\n", NRF5340_SHARED_VARIABLES->benchmark_results.encryption_measurements[i].t_end_KSGEN * TIMER_TICK_NS);
        shell_print(sh, "delta_KSGEN %f: ns\n", NRF5340_SHARED_VARIABLES->benchmark_results.encryption_measurements[i].delta_KSGEN * TIMER_TICK_NS);
        shell_print(sh, "start_ENCRYPT %f: ns\n", NRF5340_SHARED_VARIABLES->benchmark_results.encryption_measurements[i].t_start_ENDCRYPT * TIMER_TICK_NS);
        shell_print(sh, "end_ENCRYPT %f: ns\n", NRF5340_SHARED_VARIABLES->benchmark_results.encryption_measurements[i].t_end_ENDCRYPT * TIMER_TICK_NS);
        shell_print(sh, "delta_ENCRYPT %f: ns\n", NRF5340_SHARED_VARIABLES->benchmark_results.encryption_measurements[i].delta_ENDCRYPT * TIMER_TICK_NS);
        i ++;
    }

    while(j < MIN(NRF5340_SHARED_VARIABLES->benchmark_results.decryption_measurement_count, length_values_DECRYPT)) {
        shell_print(sh, "Iteration %u: \n", j);
        shell_print(sh, "start_KSGEN %f: ns\n", NRF5340_SHARED_VARIABLES->benchmark_results.decryption_measurements[j].t_start_KSGEN * TIMER_TICK_NS);
        shell_print(sh, "end_KSGEN %f: ns\n", NRF5340_SHARED_VARIABLES->benchmark_results.decryption_measurements[j].t_end_KSGEN * TIMER_TICK_NS);
        shell_print(sh, "delta_KSGEN %f: ns\n", NRF5340_SHARED_VARIABLES->benchmark_results.decryption_measurements[j].delta_KSGEN * TIMER_TICK_NS);
        shell_print(sh, "start_DECRYPT %f: ns\n", NRF5340_SHARED_VARIABLES->benchmark_results.decryption_measurements[j].t_start_ENDCRYPT * TIMER_TICK_NS);
        shell_print(sh, "end_DECRYPT %f: ns\n", NRF5340_SHARED_VARIABLES->benchmark_results.decryption_measurements[j].t_end_ENDCRYPT * TIMER_TICK_NS);
        shell_print(sh, "delta_DECRYPT %f: ns\n", NRF5340_SHARED_VARIABLES->benchmark_results.decryption_measurements[j].delta_ENDCRYPT * TIMER_TICK_NS);
        j++;
    }

    #elif defined(CONFIG_SOC_COMPATIBLE_NRF54LX)

    /* get the length of value array encryption_measurements and decryption_measurements */
    int length_values_ENCRYPT = sizeof(encryption_measurements) / sizeof(encryption_measurements[0]);
    int length_values_DECRYPT = sizeof(decryption_measurements) / sizeof(decryption_measurements[0]);

    int i = 0;
    int j = 0;

    while(i < MIN(encryption_measurement_count, length_values_ENCRYPT)) {
        shell_print(sh, "Iteration %u: \n", i);
        shell_print(sh, "start_ENCRYPT %f: ns\n", encryption_measurements[i].t_start_ENDCRYPT * TIMER_TICK_NS);
        shell_print(sh, "end_ENCRYPT %f: ns\n", encryption_measurements[i].t_end_ENDCRYPT * TIMER_TICK_NS);
        shell_print(sh, "delta_ENCRYPT %f: ns\n", encryption_measurements[i].delta_ENDCRYPT * TIMER_TICK_NS);
        i ++;
    }

    while(j < MIN(decryption_measurement_count, length_values_DECRYPT)) {
        shell_print(sh, "Iteration %u: \n", j);
        shell_print(sh, "start_DECRYPT %f: ns\n", decryption_measurements[j].t_start_ENDCRYPT * TIMER_TICK_NS);
        shell_print(sh, "end_DECRYPT %f: ns\n", decryption_measurements[j].t_end_ENDCRYPT * TIMER_TICK_NS);
        shell_print(sh, "delta_DECRYPT %f: ns\n", decryption_measurements[j].delta_ENDCRYPT * TIMER_TICK_NS);
        j++;
    }

#endif

    return 0;
}

void reset_values() {
#if defined(CONFIG_SOC_COMPATIBLE_NRF52X)
    encryption_measurement = (struct benchmark_measurement){0};
    decryption_measurement = (struct benchmark_measurement){0};
    encryption_measurement_count = 0;
    decryption_measurement_count = 0;
    memset((void *)encryption_measurements, 0, sizeof(encryption_measurements));
    memset((void *)decryption_measurements, 0, sizeof(decryption_measurements));
#elif defined(CONFIG_SOC_COMPATIBLE_NRF5340_CPUAPP)
    NRF5340_SHARED_VARIABLES->encryption_measurement = (struct benchmark_measurement){0};
    NRF5340_SHARED_VARIABLES->decryption_measurement = (struct benchmark_measurement){0};
    NRF5340_SHARED_VARIABLES->benchmark_results.encryption_measurement_count = 0;
    NRF5340_SHARED_VARIABLES->benchmark_results.decryption_measurement_count = 0;
    memset((void *)NRF5340_SHARED_VARIABLES->benchmark_results.encryption_measurements, 0, sizeof(NRF5340_SHARED_VARIABLES->benchmark_results.encryption_measurements));
    memset((void *)NRF5340_SHARED_VARIABLES->benchmark_results.decryption_measurements, 0, sizeof(NRF5340_SHARED_VARIABLES->benchmark_results.decryption_measurements));
#elif defined(CONFIG_SOC_COMPATIBLE_NRF54LX)
    encryption_measurement = (struct benchmark_measurement){0};
    decryption_measurement = (struct benchmark_measurement){0};
    encryption_measurement_count = 0;
    decryption_measurement_count = 0;
    memset((void *)encryption_measurements, 0, sizeof(encryption_measurements));
    memset((void *)decryption_measurements, 0, sizeof(decryption_measurements));
#endif
    shell_print(shell, "Values successfully reset.");
}
```

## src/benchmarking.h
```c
#pragma once

extern int cmd_benchmark();
extern int cmd_reset_sum_delta();
extern int cmd_get_delta_encryption_time();
extern int cmd_get_time_results();
```

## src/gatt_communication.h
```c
#pragma once

extern bool notify_enabled;
extern struct bt_gatt_service_static notification_srv;
extern int send_notification(struct bt_conn *conn,
                             const struct bt_gatt_attr *attr, int payload_size);
extern struct bt_gatt_subscribe_params subscribe_params;
extern struct bt_gatt_discover_params discover_params;
```

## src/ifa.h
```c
#include <zephyr/kernel.h>
#include <errno.h>
#include <stdio.h>
#include <zephyr/types.h>
#include <stddef.h>
#include <stdlib.h>
#include <string.h>

#include <zephyr/bluetooth/bluetooth.h>
//#include <zephyr/bluetooth/conn.h>
#include <zephyr/bluetooth/gatt.h>
#include <zephyr/bluetooth/hci.h>
#include <zephyr/sys/byteorder.h>
#include <zephyr/usb/usb_device.h>
#include <zephyr/drivers/uart.h>
#include <autoconf.h>
#include <zephyr/settings/settings.h>
#include <zephyr/logging/log.h>
#include <zephyr/shell/shell.h>

extern struct k_sem conn_sem;
extern struct k_sem disconn_sem;
extern struct k_sem bond_sem;

void ifa_init(const struct shell *sh);

int cmd_reset(const struct shell *sh, size_t argc, char *argv[]);

int cmd_ifa_id_save();
int cmd_ifa_id_restore();

int cmd_ifa_snapshot_take(const struct shell *sh, size_t argc, char *argv[]);
int cmd_ifa_snapshot_restore();

int cmd_ifa_stage1(const struct shell *sh, size_t argc, char *argv[]);
int cmd_ifa_stage1_periph(const struct shell *sh);
int cmd_ifa_stage2(const struct shell *sh, size_t argc, char *argv[]);
int cmd_ifa_stage2_1_periph(const struct shell *sh);
int cmd_ifa_stage2_2_periph(const struct shell *sh);
int cmd_ifa_stage3(const struct shell *sh, size_t argc, char *argv[]);
int cmd_ifa_stage4(const struct shell *sh, size_t argc, char *argv[]);

int cmd_ifa(const struct shell *sh, size_t argc, char *argv[]);
```
